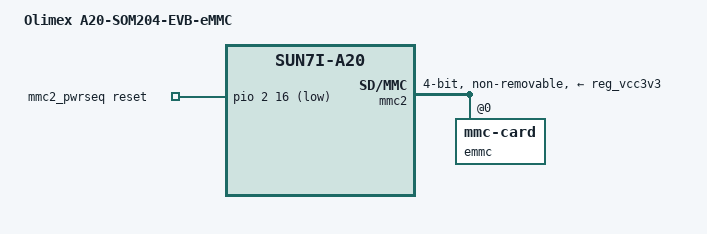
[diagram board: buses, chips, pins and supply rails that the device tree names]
// SPDX-License-Identifier: (GPL-2.0+ OR MIT)
/*
 * Device Tree Source for A20-SOM204-EVB-eMMC Board
 *
 * Copyright (C) 2018 Olimex Ltd.
 *   Author: Stefan Mavrodiev <stefan@olimex.com>
 */

/dts-v1/;
#include "sun7i-a20-olimex-som204-evb.dts"

/ {
	model = "Olimex A20-SOM204-EVB-eMMC";
	compatible = "olimex,a20-olimex-som204-evb-emmc", "allwinner,sun7i-a20";

	mmc2_pwrseq: mmc2_pwrseq {
		compatible = "mmc-pwrseq-emmc";
		reset-gpios = <&pio 2 16 GPIO_ACTIVE_LOW>;
	};
};

&mmc2 {
	vmmc-supply = <&reg_vcc3v3>;
	mmc-pwrseq = <&mmc2_pwrseq>;
	bus-width = <4>;
	non-removable;
	status = "okay";

	emmc: emmc@0 {
		reg = <0>;
		compatible = "mmc-card";
		broken-hpi;
	};
};
